# cslr_tsip register map
Vendor: Texas Instruments
Peripheral module from a debugger description file (folder c6472).
Registers are 32-bit, access not given, reset 0x0 unless marked. A register's access mark holds for its fields unless they carry their own. Offsets are as the file gives them; lines under a group give offsets from that group; [hi:lo] are bit positions; {n}, {i} and the like mark numbered series; 'fields as' and 'values as' point back to an identical list; <NAME> marks a mode.

## TSIP — TSIP MODULE REGISTERS
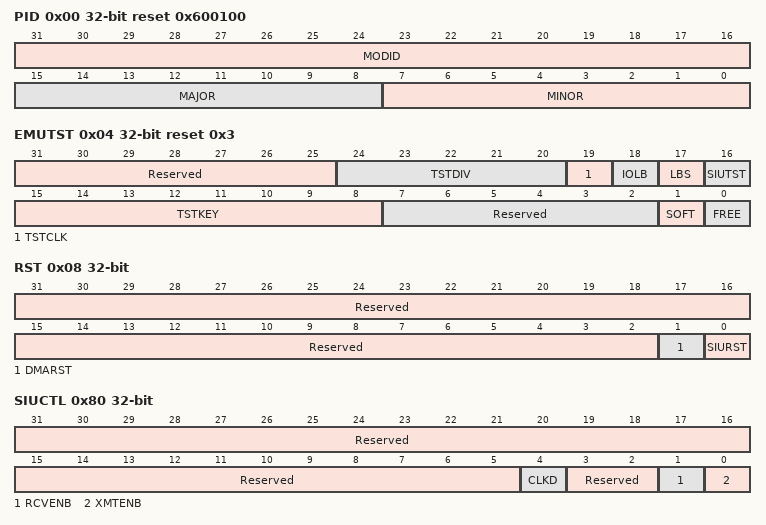
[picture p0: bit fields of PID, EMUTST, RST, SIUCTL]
0x00 PID ro reset 0x600100 — Peripheral Identification
  [31:16] MODID — Module Id
  [15:8] MAJOR — Major Version Value
  [7:0] MINOR — Minor Version Value
0x04 EMUTST reset 0x3 — Emulation and Test Register
  [31:25] Reserved — (access N)
  [24:20] TSTDIV rw — Internal Test Clock Divider Ratio
  [19] TSTCLK rw — Test Clock Source Selection
    0=EXTERNAL; 1=INTERNAL
  [18] IOLB rw — Serial Test mode selection
    0=INTERNAL_DLB; 1=IO_BUF_DLB
  [17] LBS rw — Serial Test mode selection
    0=DLB; 1=LLB
  [16] SIUTST rw — Number of MP and Shadow regions
    0=NORMAL_MODE; 1=LOOPBACK_MODE
  [15:8] TSTKEY rw — Test key
  [7:2] Reserved — (access N)
  [1] SOFT rw — Soft run selection
    0=DISABLE; 1=ENABLE
  [0] FREE rw — Free run selection
    0=DISABLE; 1=ENABLE
0x08 RST — Reset Register
  [31:2] Reserved — (access N)
  [1] DMARST rw — TDMU and DMATCU Reset
    1=RST
  [0] SIURST rw — SIU Reset
    1=RST
0x80 SIUCTL — SIU Global Control Register
  [31:5] Reserved — (access N)
  [4] CLKD rw — Clock Reduncy Selection
    0=REDUN; 1=DUAL
  [3:2] Reserved — (access N)
  [1] RCVENB rw — Receive Enable
    1=ENABLE; 0=DISABLE
  [0] XMTENB rw — Transmit Enable
    1=ENABLE; 0=DISABLE
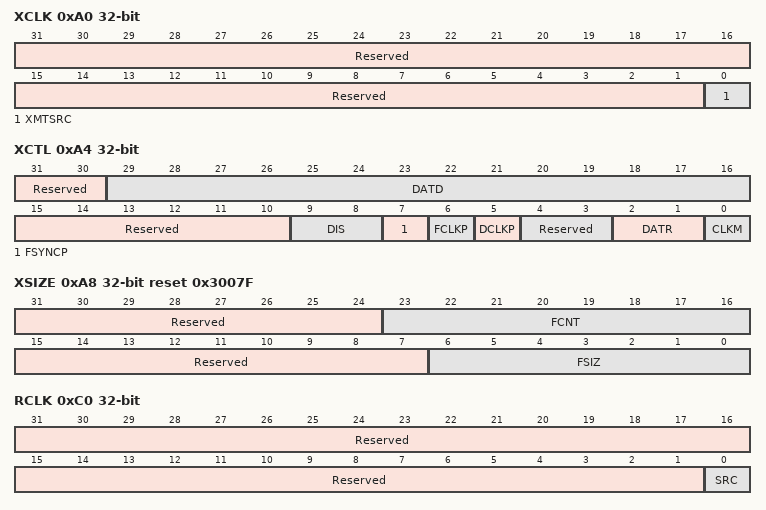
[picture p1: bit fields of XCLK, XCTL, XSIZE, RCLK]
0xA0 XCLK — Transmit Clock Source Register
  [31:1] Reserved — (access N)
  [0] XMTSRC rw — Transmit clock and frame sync selection
    0=ACLK; 1=BCLK
0xA4 XCTL — Transmit Control Register
  [31:30] Reserved — (access N)
  [29:16] DATD rw — Transmit data delay
  [15:10] Reserved — (access N)
  [9:8] DIS rw — Transmit output disable state
    0=HIMPED; 2=LOW; 3=HIGH
  [7] FSYNCP rw — Transmit frame sync polarity
    0=ALOW; 1=AHIGH
  [6] FCLKP rw — Transmit frame sync clock polarity
    0=RISING; 1=FALLING
  [5] DCLKP rw — Transmit data clock polarity
    0=RISING; 1=FALLING
  [4:3] Reserved — (access N)
  [2:1] DATR rw — Transmit data rate
    0=8M; 1=16M; 2=32M
  [0] CLKM rw — Transmit clock mode
    0=DBL; 1=SGL
0xA8 XSIZE reset 0x3007F — Transmit Size Register
  [31:24] Reserved — (access N)
  [23:16] FCNT rw — Transmit Frame count
  [15:7] Reserved — (access N)
  [6:0] FSIZ rw — Transmit Frame Size
0xC0 RCLK — Receive Clock Source Register
  [31:1] Reserved — (access N)
  [0] SRC rw — Receive clocl and frame sync selection
    0=ACLK; 1=BCLK
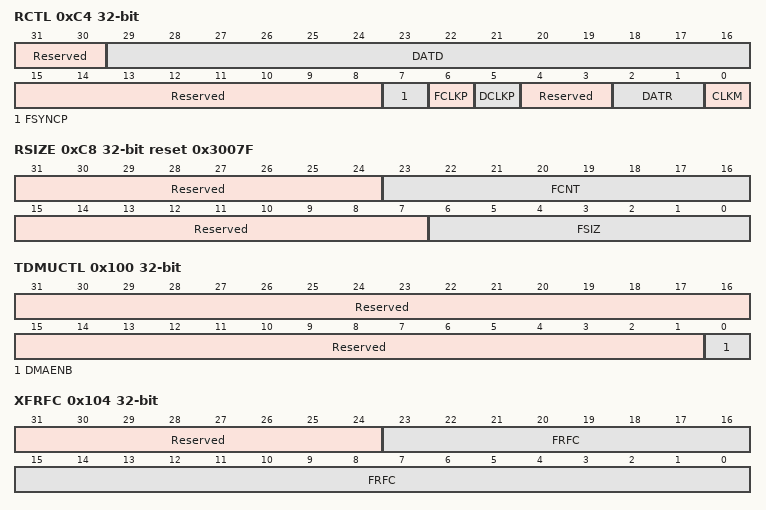
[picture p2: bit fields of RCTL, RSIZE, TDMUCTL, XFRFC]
0xC4 RCTL — Receive Control Register
  [31:30] Reserved — (access N)
  [29:16] DATD rw — Receive data delay
  [15:8] Reserved — (access N)
  [7] FSYNCP rw — Receive frame sync polarity
    0=ALOW; 1=AHIGH
  [6] FCLKP rw — Receive frame sync clock polarity
    0=RISING; 1=FALLING
  [5] DCLKP rw — Receive data clock polarity
    0=RISING; 1=FALLING
  [4:3] Reserved — (access N)
  [2:1] DATR rw — Receive Data rate
    0=8M; 1=16M; 2=32M
  [0] CLKM rw — Receive clock mode
    0=DBL; 1=SGL
0xC8 RSIZE reset 0x3007F — Receive size registers
  [31:24] Reserved — (access N)
  [23:16] FCNT rw — Receive frame count
  [15:7] Reserved — (access N)
  [6:0] FSIZ rw — Receive frme size
0x100 TDMUCTL — TDMU Global Control Register
  [31:1] Reserved — (access N)
  [0] DMAENB rw — TDMU and DMATCU enable
    1=ENB; 0=DIS
0x104 XFRFC — Transmit Free Running Frame Counter
  [31:24] Reserved — (access N)
  [23:0] FRFC ro — Free Running Frame Counter
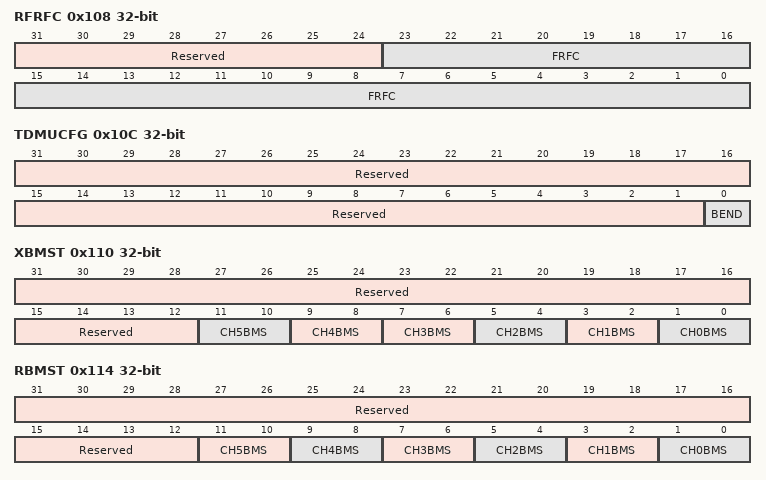
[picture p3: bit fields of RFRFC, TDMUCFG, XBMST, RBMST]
0x108 RFRFC — Receive Free Running Frame Counter
  fields as XFRFC
0x10C TDMUCFG — TDMU Global Configuration Register
  [31:1] Reserved — (access N)
  [0] BEND rw — Endian Mode Selection
    0=LITTLE; 1=BIG
0x110 XBMST — Transmit Channel Bitmap Active Status Register
  [31:12] Reserved — (access N)
  [11:10] CH5BMS ro — Transmit Channel 5 active status
  [9:8] CH4BMS ro — Transmit chaneel 4 active status
  [2n+1:2n] CH{n}BMS ro (n=0..3) — Transmit channel {n} active status
0x114 RBMST — Receive Channel Bitmap Active Status Register
  [31:12] Reserved — (access N)
  [2n+1:2n] CH{n}BMS ro (n=0..5) — Receive Channel {n} status
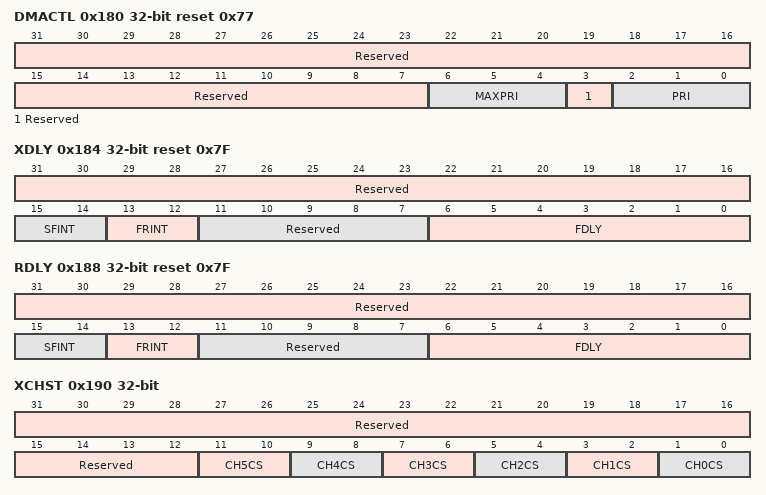
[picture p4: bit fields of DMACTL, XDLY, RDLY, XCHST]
0x180 DMACTL reset 0x77 — DMATCU Global Control Register
  [31:7] Reserved — (access N)
  [6:4] MAXPRI rw — Maximum Transfer Priority
  [3] Reserved — (access N)
  [2:0] PRI rw — Transfer Priority
0x184 XDLY reset 0x7F — Transmit timeslot delay counter
  [31:16] Reserved — (access N)
  [15:14] SFINT ro — Transmit Superframe interrupt selection
    0=ACK; 1=DLY; 2=ACKORDLY; 3=ACKNDLY
  [13:12] FRINT ro — Transmit Frame interrupt selection
    0=ACK; 1=DLY; 2=ACKORDLY; 3=ACKNDLY
  [11:7] Reserved — (access N)
  [6:0] FDLY rw — Transmit frame interrupt delay
0x188 RDLY reset 0x7F — Receive Timeslot Delay Counter
  [31:16] Reserved — (access N)
  [15:14] SFINT ro — Receive superframe interrupt selection
    0=ACK; 1=DLY; 2=ACKORDLY; 3=ACKNDLY
  [13:12] FRINT ro — Receive Frame interrupt selection
    0=ACK; 1=DLY; 2=ACKORDLY; 3=ACKNDLY
  [11:7] Reserved — (access N)
  [6:0] FDLY rw — Receive frame interrupt delay
0x190 XCHST — Transmit channel Configuration active status register
  [31:12] Reserved — (access N)
  [2n+1:2n] CH{n}CS ro (n=0..5) — Transmit channel {n} active status
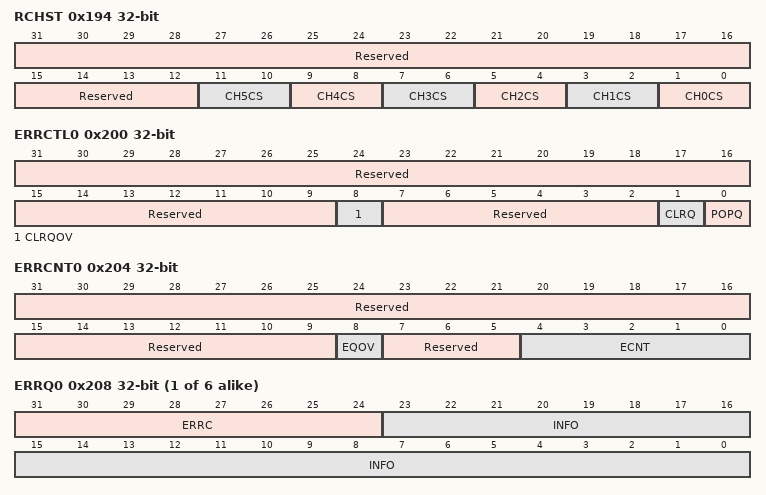
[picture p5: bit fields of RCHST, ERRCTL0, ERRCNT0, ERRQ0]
0x194 RCHST — Receive channel Configuration active status register
  [31:12] Reserved — (access N)
  [11:10] CH5CS ro — Receive channel 5 active status
  [9:8] CH4CS ro — Receive channel 4 active status
  [7:6] CH3CS ro — Receiev channel 3 active status
  [5:4] CH2CS ro — Receive channel 2 active status
  [3:2] CH1CS ro — Receive channel 1 active status
  [1:0] CH0CS ro — Receive channel 0 active status
0x200 ERRCTL0 — Transmit/Receive channel error control register {ERR_CTL}
  [31:9] Reserved — (access N)
  [8] CLRQOV rw — Clear error queue overflow flag
    1=CLR
  [7:2] Reserved — (access N)
  [1] CLRQ rw — Clear error queue
    1=CLR
  [0] POPQ rw — Pop the top entity off the error queue
    1=POP
0x200 ERRCTL0 — Transmit/Receive channel error control register {ERR_CTL}
  fields as ERRCTL0
0x204 ERRCNT0 — Transmit/Receive channel error count register {ERR_CNT}
  [31:9] Reserved — (access N)
  [8] EQOV ro — Error queue overflow
  [7:5] Reserved — (access N)
  [4:0] ECNT ro — Error count
{0x208+0x10*i} ERRQ{i} ro (i=0..5) — Transmit/Receive channel error queue register
  [31:24] ERRC — Error Code
  [23:0] INFO — Error information field
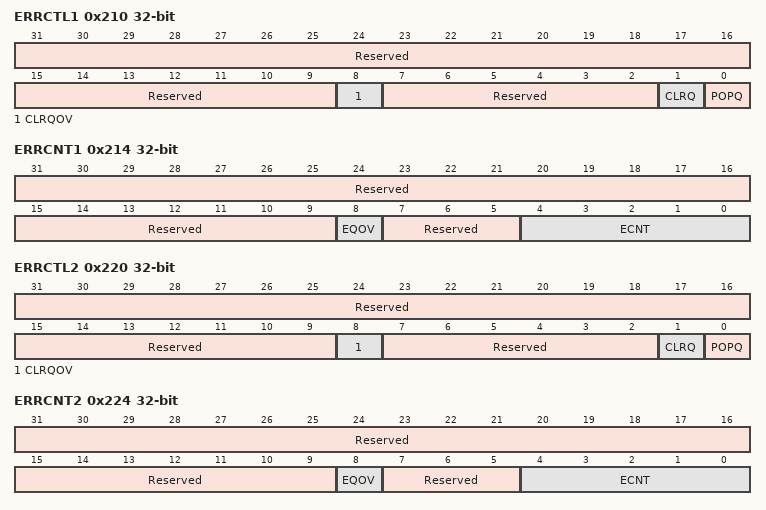
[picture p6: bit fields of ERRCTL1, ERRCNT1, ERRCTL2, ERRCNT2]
0x210 ERRCTL1 — Transmit/Receive channel error control register {ERR_CTL}
  fields as ERRCTL0
0x214 ERRCNT1 — Transmit/Receive channel error count register {ERR_CNT}
  fields as ERRCNT0
0x220 ERRCTL2 — Transmit/Receive channel error control register {ERR_CTL}
  fields as ERRCTL0
0x224 ERRCNT2 — Transmit/Receive channel error count register {ERR_CNT}
  fields as ERRCNT0
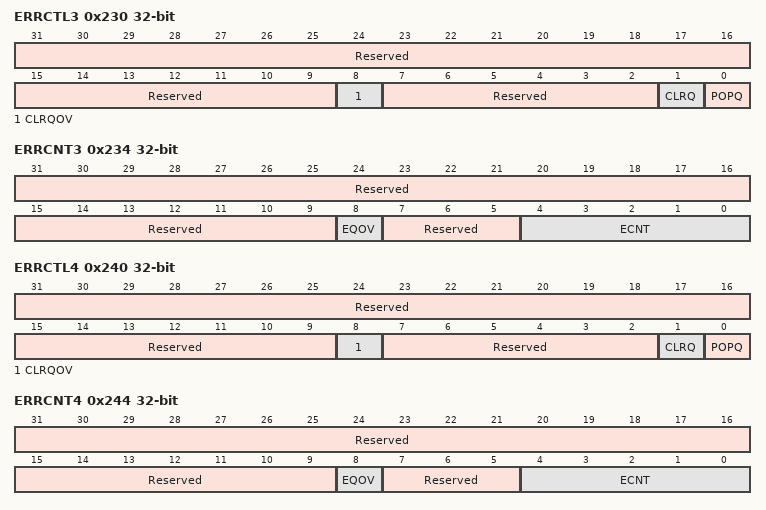
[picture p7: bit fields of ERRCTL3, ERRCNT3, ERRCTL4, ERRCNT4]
0x230 ERRCTL3 — Transmit/Receive channel error control register {ERR_CTL}
  fields as ERRCTL0
0x234 ERRCNT3 — Transmit/Receive channel error count register {ERR_CNT}
  fields as ERRCNT0
0x240 ERRCTL4 — Transmit/Receive channel error control register {ERR_CTL}
  fields as ERRCTL0
0x244 ERRCNT4 — Transmit/Receive channel error count register {ERR_CNT}
  fields as ERRCNT0
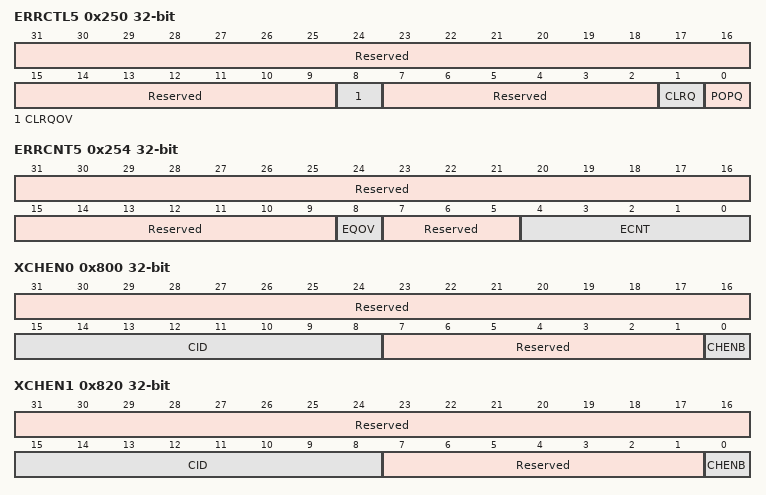
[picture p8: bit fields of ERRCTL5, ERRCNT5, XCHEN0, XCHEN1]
0x250 ERRCTL5 — Transmit/Receive channel error control register {ERR_CTL}
  fields as ERRCTL0
0x254 ERRCNT5 — Transmit/Receive channel error count register {ERR_CNT}
  fields as ERRCNT0
0x800 XCHEN0 — TDMU Transmit Channel Enable Register {XCHEN_XCHEN}
  [31:16] Reserved — (access N)
  [15:8] CID rw — configuration Identification
  [7:1] Reserved — (access N)
  [0] CHENB rw — Channel n enable
    1=ENB; 0=DIS
0x820 XCHEN1 — TDMU Transmit Channel Enable Register {XCHEN_XCHEN}
  fields as XCHEN0
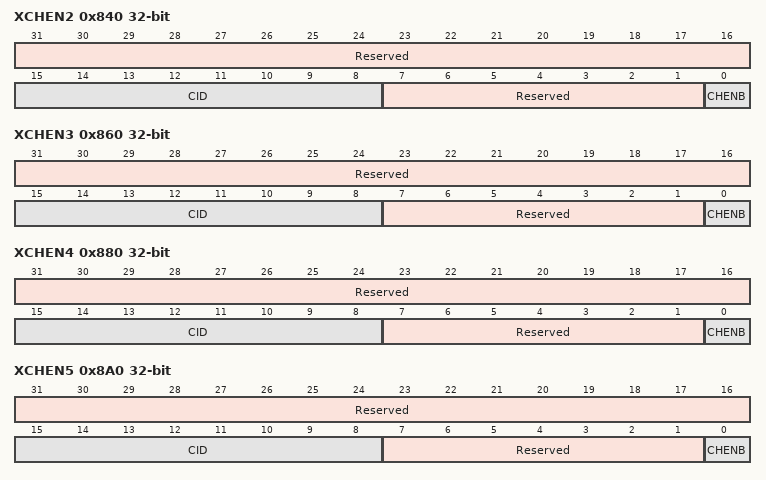
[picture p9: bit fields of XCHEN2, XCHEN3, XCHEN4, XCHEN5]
0x840 XCHEN2 — TDMU Transmit Channel Enable Register {XCHEN_XCHEN}
  fields as XCHEN0
0x860 XCHEN3 — TDMU Transmit Channel Enable Register {XCHEN_XCHEN}
  fields as XCHEN0
0x880 XCHEN4 — TDMU Transmit Channel Enable Register {XCHEN_XCHEN}
  fields as XCHEN0
0x8A0 XCHEN5 — TDMU Transmit Channel Enable Register {XCHEN_XCHEN}
  fields as XCHEN0
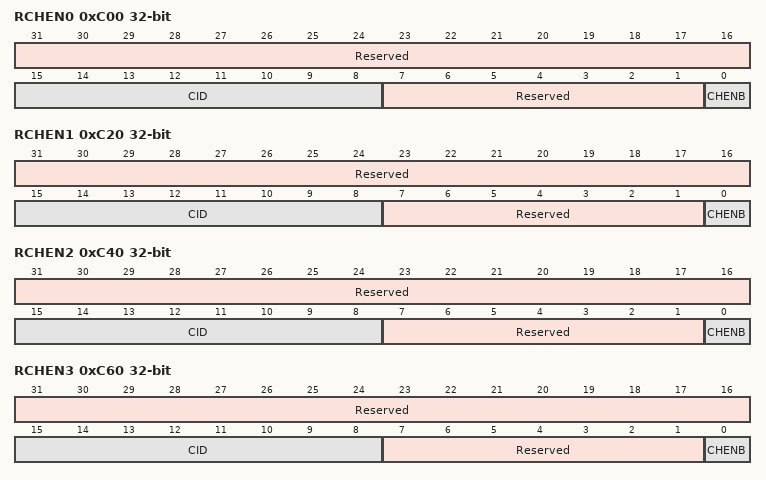
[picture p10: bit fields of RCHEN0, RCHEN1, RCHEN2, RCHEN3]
0xC00 RCHEN0 — TDMU Receive Channel Enable Register {RCHEN_RCHEN}
  fields as XCHEN0
0xC20 RCHEN1 — TDMU Receive Channel Enable Register {RCHEN_RCHEN}
  fields as XCHEN0
0xC40 RCHEN2 — TDMU Receive Channel Enable Register {RCHEN_RCHEN}
  fields as XCHEN0
0xC60 RCHEN3 — TDMU Receive Channel Enable Register {RCHEN_RCHEN}
  fields as XCHEN0
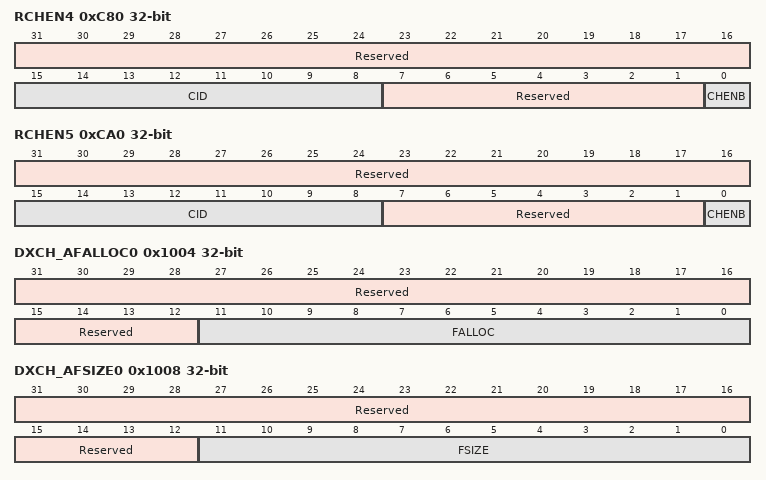
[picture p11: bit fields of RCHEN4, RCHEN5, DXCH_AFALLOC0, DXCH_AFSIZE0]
0xC80 RCHEN4 — TDMU Receive Channel Enable Register {RCHEN_RCHEN}
  fields as XCHEN0
0xCA0 RCHEN5 — TDMU Receive Channel Enable Register {RCHEN_RCHEN}
  fields as XCHEN0
0x1000 DXCH_ABASE0 rw — DMATCU Receive Channel Memory Base Address Register A {DXCH_ABASE}
  [31:0] BADDR — Memory Buffer Base Address
0x1004 DXCH_AFALLOC0 — DMATCU Receive Channel Frame Allocation Register A {DXCH_AFALLOC}
  [31:12] Reserved — (access N)
  [11:0] FALLOC rw — Frame Buffer Allocation
0x1008 DXCH_AFSIZE0 — DMATCU Receive Channel Frame Size Register A {DXCH_AFSIZE}
  [31:12] Reserved — (access N)
  [11:0] FSIZE rw — Frame Size
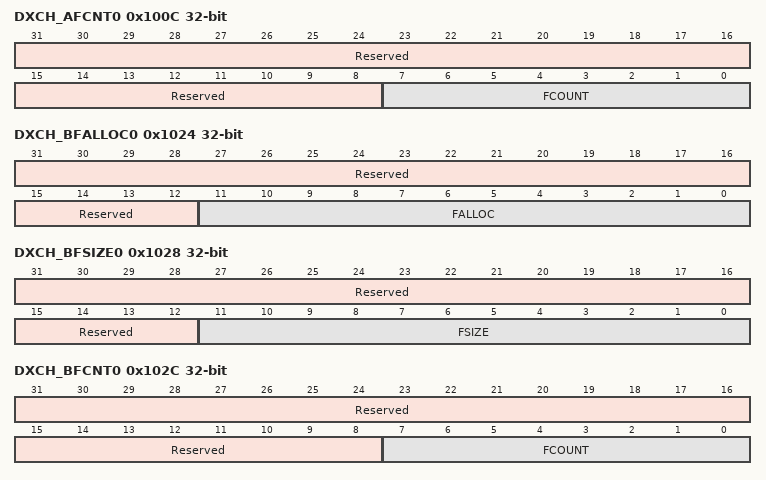
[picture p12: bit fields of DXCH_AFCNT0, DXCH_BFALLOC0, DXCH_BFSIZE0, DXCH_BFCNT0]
0x100C DXCH_AFCNT0 — DMATCU Receive Channel Frame Count Register A {DXCH_AFCNT}
  [31:8] Reserved — (access N)
  [7:0] FCOUNT rw — Frame count
0x1020 DXCH_BBASE0 rw — DMATCU Receive Channel Memory Base Address Register B {DXCH_BBASE}
  [31:0] BADDR — Memory Buffer Base Address
0x1024 DXCH_BFALLOC0 — DMATCU Receive Channel Frame Allocation Register B {DXCH_BFALLOC}
  fields as DXCH_AFALLOC0
0x1028 DXCH_BFSIZE0 — DMATCU Receive Channel Frame Size Register B {DXCH_BFSIZE}
  [31:12] Reserved — (access N)
  [11:0] FSIZE rw — Frame Size
0x102C DXCH_BFCNT0 — DMATCU Receive Channel Frame Count Register B {DXCH_BFCNT}
  [31:8] Reserved — (access N)
  [7:0] FCOUNT rw — Frame count
0x1040 DXCH_ABASE1 rw — DMATCU Receive Channel Memory Base Address Register A {DXCH_ABASE}
  [31:0] BADDR — Memory Buffer Base Address
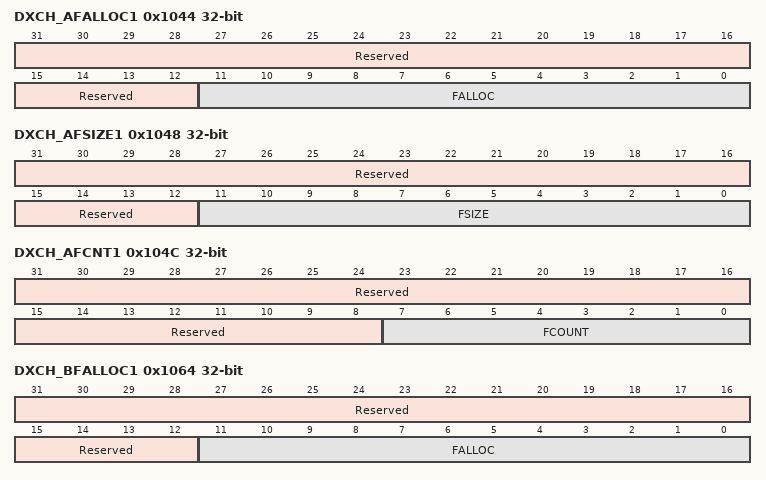
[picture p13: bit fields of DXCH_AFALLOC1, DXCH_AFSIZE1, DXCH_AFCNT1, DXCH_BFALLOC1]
0x1044 DXCH_AFALLOC1 — DMATCU Receive Channel Frame Allocation Register A {DXCH_AFALLOC}
  fields as DXCH_AFALLOC0
0x1048 DXCH_AFSIZE1 — DMATCU Receive Channel Frame Size Register A {DXCH_AFSIZE}
  [31:12] Reserved — (access N)
  [11:0] FSIZE rw — Frame Size
0x104C DXCH_AFCNT1 — DMATCU Receive Channel Frame Count Register A {DXCH_AFCNT}
  [31:8] Reserved — (access N)
  [7:0] FCOUNT rw — Frame count
0x1060 DXCH_BBASE1 rw — DMATCU Receive Channel Memory Base Address Register B {DXCH_BBASE}
  [31:0] BADDR — Memory Buffer Base Address
0x1064 DXCH_BFALLOC1 — DMATCU Receive Channel Frame Allocation Register B {DXCH_BFALLOC}
  fields as DXCH_AFALLOC0
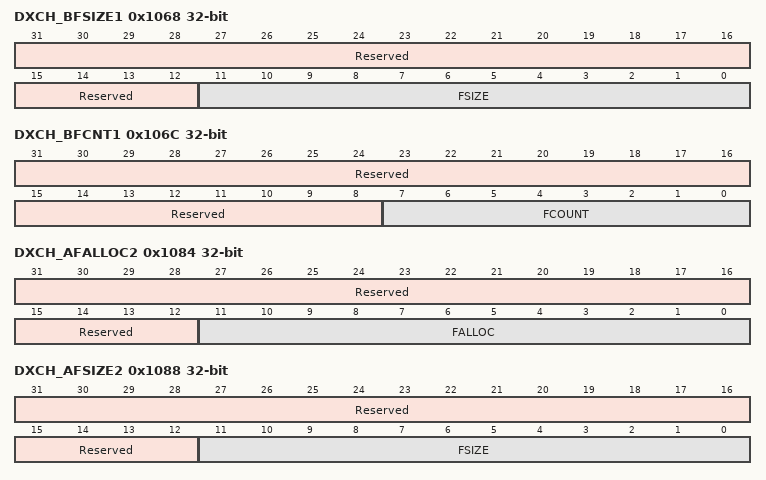
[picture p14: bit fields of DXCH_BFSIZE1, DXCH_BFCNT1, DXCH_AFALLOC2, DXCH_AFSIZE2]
0x1068 DXCH_BFSIZE1 — DMATCU Receive Channel Frame Size Register B {DXCH_BFSIZE}
  [31:12] Reserved — (access N)
  [11:0] FSIZE rw — Frame Size
0x106C DXCH_BFCNT1 — DMATCU Receive Channel Frame Count Register B {DXCH_BFCNT}
  [31:8] Reserved — (access N)
  [7:0] FCOUNT rw — Frame count
0x1080 DXCH_ABASE2 rw — DMATCU Receive Channel Memory Base Address Register A {DXCH_ABASE}
  [31:0] BADDR — Memory Buffer Base Address
0x1084 DXCH_AFALLOC2 — DMATCU Receive Channel Frame Allocation Register A {DXCH_AFALLOC}
  fields as DXCH_AFALLOC0
0x1088 DXCH_AFSIZE2 — DMATCU Receive Channel Frame Size Register A {DXCH_AFSIZE}
  [31:12] Reserved — (access N)
  [11:0] FSIZE rw — Frame Size
0x108C DXCH_AFCNT2 — DMATCU Receive Channel Frame Count Register A {DXCH_AFCNT}
  [31:8] Reserved — (access N)
  [7:0] FCOUNT rw — Frame count
0x10A0 DXCH_BBASE2 rw — DMATCU Receive Channel Memory Base Address Register B {DXCH_BBASE}
  [31:0] BADDR — Memory Buffer Base Address
0x10A4 DXCH_BFALLOC2 — DMATCU Receive Channel Frame Allocation Register B {DXCH_BFALLOC}
  fields as DXCH_AFALLOC0
0x10A8 DXCH_BFSIZE2 — DMATCU Receive Channel Frame Size Register B {DXCH_BFSIZE}
  [31:12] Reserved — (access N)
  [11:0] FSIZE rw — Frame Size
0x10AC DXCH_BFCNT2 — DMATCU Receive Channel Frame Count Register B {DXCH_BFCNT}
  [31:8] Reserved — (access N)
  [7:0] FCOUNT rw — Frame count
0x10C0 DXCH_ABASE3 rw — DMATCU Receive Channel Memory Base Address Register A {DXCH_ABASE}
  [31:0] BADDR — Memory Buffer Base Address
0x10C4 DXCH_AFALLOC3 — DMATCU Receive Channel Frame Allocation Register A {DXCH_AFALLOC}
  fields as DXCH_AFALLOC0
0x10C8 DXCH_AFSIZE3 — DMATCU Receive Channel Frame Size Register A {DXCH_AFSIZE}
  [31:12] Reserved — (access N)
  [11:0] FSIZE rw — Frame Size
0x10CC DXCH_AFCNT3 — DMATCU Receive Channel Frame Count Register A {DXCH_AFCNT}
  [31:8] Reserved — (access N)
  [7:0] FCOUNT rw — Frame count
0x10E0 DXCH_BBASE3 rw — DMATCU Receive Channel Memory Base Address Register B {DXCH_BBASE}
  [31:0] BADDR — Memory Buffer Base Address
0x10E4 DXCH_BFALLOC3 — DMATCU Receive Channel Frame Allocation Register B {DXCH_BFALLOC}
  fields as DXCH_AFALLOC0
0x10E8 DXCH_BFSIZE3 — DMATCU Receive Channel Frame Size Register B {DXCH_BFSIZE}
  [31:12] Reserved — (access N)
  [11:0] FSIZE rw — Frame Size
0x10EC DXCH_BFCNT3 — DMATCU Receive Channel Frame Count Register B {DXCH_BFCNT}
  [31:8] Reserved — (access N)
  [7:0] FCOUNT rw — Frame count
0x1100 DXCH_ABASE4 rw — DMATCU Receive Channel Memory Base Address Register A {DXCH_ABASE}
  [31:0] BADDR — Memory Buffer Base Address
0x1104 DXCH_AFALLOC4 — DMATCU Receive Channel Frame Allocation Register A {DXCH_AFALLOC}
  fields as DXCH_AFALLOC0
0x1108 DXCH_AFSIZE4 — DMATCU Receive Channel Frame Size Register A {DXCH_AFSIZE}
  [31:12] Reserved — (access N)
  [11:0] FSIZE rw — Frame Size
0x110C DXCH_AFCNT4 — DMATCU Receive Channel Frame Count Register A {DXCH_AFCNT}
  [31:8] Reserved — (access N)
  [7:0] FCOUNT rw — Frame count
0x1120 DXCH_BBASE4 rw — DMATCU Receive Channel Memory Base Address Register B {DXCH_BBASE}
  [31:0] BADDR — Memory Buffer Base Address
0x1124 DXCH_BFALLOC4 — DMATCU Receive Channel Frame Allocation Register B {DXCH_BFALLOC}
  fields as DXCH_AFALLOC0
0x1128 DXCH_BFSIZE4 — DMATCU Receive Channel Frame Size Register B {DXCH_BFSIZE}
  [31:12] Reserved — (access N)
  [11:0] FSIZE rw — Frame Size
0x112C DXCH_BFCNT4 — DMATCU Receive Channel Frame Count Register B {DXCH_BFCNT}
  [31:8] Reserved — (access N)
  [7:0] FCOUNT rw — Frame count
0x1140 DXCH_ABASE5 rw — DMATCU Receive Channel Memory Base Address Register A {DXCH_ABASE}
  [31:0] BADDR — Memory Buffer Base Address
0x1144 DXCH_AFALLOC5 — DMATCU Receive Channel Frame Allocation Register A {DXCH_AFALLOC}
  fields as DXCH_AFALLOC0
0x1148 DXCH_AFSIZE5 — DMATCU Receive Channel Frame Size Register A {DXCH_AFSIZE}
  [31:12] Reserved — (access N)
  [11:0] FSIZE rw — Frame Size
0x114C DXCH_AFCNT5 — DMATCU Receive Channel Frame Count Register A {DXCH_AFCNT}
  [31:8] Reserved — (access N)
  [7:0] FCOUNT rw — Frame count
0x1160 DXCH_BBASE5 rw — DMATCU Receive Channel Memory Base Address Register B {DXCH_BBASE}
  [31:0] BADDR — Memory Buffer Base Address
0x1164 DXCH_BFALLOC5 — DMATCU Receive Channel Frame Allocation Register B {DXCH_BFALLOC}
  fields as DXCH_AFALLOC0
0x1168 DXCH_BFSIZE5 — DMATCU Receive Channel Frame Size Register B {DXCH_BFSIZE}
  [31:12] Reserved — (access N)
  [11:0] FSIZE rw — Frame Size
0x116C DXCH_BFCNT5 — DMATCU Receive Channel Frame Count Register B {DXCH_BFCNT}
  [31:8] Reserved — (access N)
  [7:0] FCOUNT rw — Frame count
0x1800 DRCH_ABASE0 rw — DMATCU Receive Channel Memory Base Address Register A {DRCH_ABASE}
  [31:0] BADDR — Memory Buffer Base Address
0x1804 DRCH_AFALLOC0 — DMATCU Receive Channel Frame Allocation Register A {DRCH_AFALLOC}
  fields as DXCH_AFALLOC0
0x1808 DRCH_AFSIZE0 — DMATCU Receive Channel Frame Size Register A {DRCH_AFSIZE}
  [31:12] Reserved — (access N)
  [11:0] FSIZE rw — Frame Size
0x180C DRCH_AFCNT0 — DMATCU Receive Channel Frame Count Register A {DRCH_AFCNT}
  [31:8] Reserved — (access N)
  [7:0] FCOUNT rw — Frame count
0x1820 DRCH_BBASE0 rw — DMATCU Receive Channel Memory Base Address Register B {DRCH_BBASE}
  [31:0] BADDR — Memory Buffer Base Address
0x1824 DRCH_BFALLOC0 — DMATCU Receive Channel Frame Allocation Register B {DRCH_BFALLOC}
  fields as DXCH_AFALLOC0
0x1828 DRCH_BFSIZE0 — DMATCU Receive Channel Frame Size Register B {DRCH_BFSIZE}
  [31:12] Reserved — (access N)
  [11:0] FSIZE rw — Frame Size
0x182C DRCH_BFCNT0 — DMATCU Receive Channel Frame Count Register B {DRCH_BFCNT}
  [31:8] Reserved — (access N)
  [7:0] FCOUNT rw — Frame count
0x1840 DRCH_ABASE1 rw — DMATCU Receive Channel Memory Base Address Register A {DRCH_ABASE}
  [31:0] BADDR — Memory Buffer Base Address
0x1844 DRCH_AFALLOC1 — DMATCU Receive Channel Frame Allocation Register A {DRCH_AFALLOC}
  fields as DXCH_AFALLOC0
0x1848 DRCH_AFSIZE1 — DMATCU Receive Channel Frame Size Register A {DRCH_AFSIZE}
  [31:12] Reserved — (access N)
  [11:0] FSIZE rw — Frame Size
0x184C DRCH_AFCNT1 — DMATCU Receive Channel Frame Count Register A {DRCH_AFCNT}
  [31:8] Reserved — (access N)
  [7:0] FCOUNT rw — Frame count
0x1860 DRCH_BBASE1 rw — DMATCU Receive Channel Memory Base Address Register B {DRCH_BBASE}
  [31:0] BADDR — Memory Buffer Base Address
0x1864 DRCH_BFALLOC1 — DMATCU Receive Channel Frame Allocation Register B {DRCH_BFALLOC}
  fields as DXCH_AFALLOC0
0x1868 DRCH_BFSIZE1 — DMATCU Receive Channel Frame Size Register B {DRCH_BFSIZE}
  [31:12] Reserved — (access N)
  [11:0] FSIZE rw — Frame Size
0x186C DRCH_BFCNT1 — DMATCU Receive Channel Frame Count Register B {DRCH_BFCNT}
  [31:8] Reserved — (access N)
  [7:0] FCOUNT rw — Frame count
0x1880 DRCH_ABASE2 rw — DMATCU Receive Channel Memory Base Address Register A {DRCH_ABASE}
  [31:0] BADDR — Memory Buffer Base Address
0x1884 DRCH_AFALLOC2 — DMATCU Receive Channel Frame Allocation Register A {DRCH_AFALLOC}
  fields as DXCH_AFALLOC0
0x1888 DRCH_AFSIZE2 — DMATCU Receive Channel Frame Size Register A {DRCH_AFSIZE}
  [31:12] Reserved — (access N)
  [11:0] FSIZE rw — Frame Size
0x188C DRCH_AFCNT2 — DMATCU Receive Channel Frame Count Register A {DRCH_AFCNT}
  [31:8] Reserved — (access N)
  [7:0] FCOUNT rw — Frame count
0x18A0 DRCH_BBASE2 rw — DMATCU Receive Channel Memory Base Address Register B {DRCH_BBASE}
  [31:0] BADDR — Memory Buffer Base Address
0x18A4 DRCH_BFALLOC2 — DMATCU Receive Channel Frame Allocation Register B {DRCH_BFALLOC}
  fields as DXCH_AFALLOC0
0x18A8 DRCH_BFSIZE2 — DMATCU Receive Channel Frame Size Register B {DRCH_BFSIZE}
  [31:12] Reserved — (access N)
  [11:0] FSIZE rw — Frame Size
0x18AC DRCH_BFCNT2 — DMATCU Receive Channel Frame Count Register B {DRCH_BFCNT}
  [31:8] Reserved — (access N)
  [7:0] FCOUNT rw — Frame count
0x18C0 DRCH_ABASE3 rw — DMATCU Receive Channel Memory Base Address Register A {DRCH_ABASE}
  [31:0] BADDR — Memory Buffer Base Address
0x18C4 DRCH_AFALLOC3 — DMATCU Receive Channel Frame Allocation Register A {DRCH_AFALLOC}
  fields as DXCH_AFALLOC0
0x18C8 DRCH_AFSIZE3 — DMATCU Receive Channel Frame Size Register A {DRCH_AFSIZE}
  [31:12] Reserved — (access N)
  [11:0] FSIZE rw — Frame Size
0x18CC DRCH_AFCNT3 — DMATCU Receive Channel Frame Count Register A {DRCH_AFCNT}
  [31:8] Reserved — (access N)
  [7:0] FCOUNT rw — Frame count
0x18E0 DRCH_BBASE3 rw — DMATCU Receive Channel Memory Base Address Register B {DRCH_BBASE}
  [31:0] BADDR — Memory Buffer Base Address
0x18E4 DRCH_BFALLOC3 — DMATCU Receive Channel Frame Allocation Register B {DRCH_BFALLOC}
  fields as DXCH_AFALLOC0
0x18E8 DRCH_BFSIZE3 — DMATCU Receive Channel Frame Size Register B {DRCH_BFSIZE}
  [31:12] Reserved — (access N)
  [11:0] FSIZE rw — Frame Size
0x18EC DRCH_BFCNT3 — DMATCU Receive Channel Frame Count Register B {DRCH_BFCNT}
  [31:8] Reserved — (access N)
  [7:0] FCOUNT rw — Frame count
0x1900 DRCH_ABASE4 rw — DMATCU Receive Channel Memory Base Address Register A {DRCH_ABASE}
  [31:0] BADDR — Memory Buffer Base Address
0x1904 DRCH_AFALLOC4 — DMATCU Receive Channel Frame Allocation Register A {DRCH_AFALLOC}
  fields as DXCH_AFALLOC0
0x1908 DRCH_AFSIZE4 — DMATCU Receive Channel Frame Size Register A {DRCH_AFSIZE}
  [31:12] Reserved — (access N)
  [11:0] FSIZE rw — Frame Size
0x190C DRCH_AFCNT4 — DMATCU Receive Channel Frame Count Register A {DRCH_AFCNT}
  [31:8] Reserved — (access N)
  [7:0] FCOUNT rw — Frame count
0x1920 DRCH_BBASE4 rw — DMATCU Receive Channel Memory Base Address Register B {DRCH_BBASE}
  [31:0] BADDR — Memory Buffer Base Address
0x1924 DRCH_BFALLOC4 — DMATCU Receive Channel Frame Allocation Register B {DRCH_BFALLOC}
  fields as DXCH_AFALLOC0
0x1928 DRCH_BFSIZE4 — DMATCU Receive Channel Frame Size Register B {DRCH_BFSIZE}
  [31:12] Reserved — (access N)
  [11:0] FSIZE rw — Frame Size
0x192C DRCH_BFCNT4 — DMATCU Receive Channel Frame Count Register B {DRCH_BFCNT}
  [31:8] Reserved — (access N)
  [7:0] FCOUNT rw — Frame count
0x1940 DRCH_ABASE5 rw — DMATCU Receive Channel Memory Base Address Register A {DRCH_ABASE}
  [31:0] BADDR — Memory Buffer Base Address
0x1944 DRCH_AFALLOC5 — DMATCU Receive Channel Frame Allocation Register A {DRCH_AFALLOC}
  fields as DXCH_AFALLOC0
0x1948 DRCH_AFSIZE5 — DMATCU Receive Channel Frame Size Register A {DRCH_AFSIZE}
  [31:12] Reserved — (access N)
  [11:0] FSIZE rw — Frame Size
0x194C DRCH_AFCNT5 — DMATCU Receive Channel Frame Count Register A {DRCH_AFCNT}
  [31:8] Reserved — (access N)
  [7:0] FCOUNT rw — Frame count
0x1960 DRCH_BBASE5 rw — DMATCU Receive Channel Memory Base Address Register B {DRCH_BBASE}
  [31:0] BADDR — Memory Buffer Base Address
0x1964 DRCH_BFALLOC5 — DMATCU Receive Channel Frame Allocation Register B {DRCH_BFALLOC}
  fields as DXCH_AFALLOC0
0x1968 DRCH_BFSIZE5 — DMATCU Receive Channel Frame Size Register B {DRCH_BFSIZE}
  [31:12] Reserved — (access N)
  [11:0] FSIZE rw — Frame Size
0x196C DRCH_BFCNT5 — DMATCU Receive Channel Frame Count Register B {DRCH_BFCNT}
  [31:8] Reserved — (access N)
  [7:0] FCOUNT rw — Frame count
{0x8000+0x200*i} XBM_RBMA{i}[64] rw (i=0..5) — Transmit Channel Bitmap A
  [31:0] CH — Reserved
{0x8100+0x200*i} XBM_RBMB{i}[64] rw (i=0..5) — Transmit Channel Bitmap B
  [31:0] CH — Reserved
{0xC000+0x200*i} RBM_RBMA{i}[64] rw (i=0..5) — Receive Channel Bitmap A
  [31:0] CH — Reserved
{0xC100+0x200*i} RBM_RBMB{i}[64] rw (i=0..5) — Receive Channel Bitmap B
  [31:0] CH — Reserved
{0x10000+0x800*i} XPING{i} rw (i=0..2) — Transmit Channel {i} Ping buffer
  [31:0] DAT — Reserved
{0x10400+0x800*i} XPONG{i} rw (i=0..2) — Transmit Channel {i} Pong buffer
  [31:0] DAT — Reserved
0x11800 XPING3 rw — Transmit Channel 0 Ping buffer
  [31:0] DAT — Reserved
0x11C00 XPONG3 rw — Transmit Channel 0 Pong buffer
  [31:0] DAT — Reserved
0x12000 XPING4 rw — Transmit Channel 4 Ping buffer
  [31:0] DAT — Reserved
0x12400 XPONG4 rw — Transmit Channel 4 Ping buffer
  [31:0] DAT — Reserved
0x12800 XPING5 rw — Transmit Channel 5 Ping buffer
  [31:0] DAT — Reserved
0x12C00 XPONG5 rw — Transmit Channel 5 Pong buffer
  [31:0] DAT — Reserved
{0x18000+0x800*i} RPING{i} rw (i=0..2) — Receive Channel {i} Ping buffer
  [31:0] DAT — Reserved
{0x18400+0x800*i} RPONG{i} rw (i=0..2) — Receive Channel {i} Pong buffer
  [31:0] DAT — Reserved
0x19800 RPING3 rw — Receive Channel 0 Ping buffer
  [31:0] DAT — Reserved
0x19C00 RPONG3 rw — Receive Channel 0 Pong buffer
  [31:0] DAT — Reserved
0x1A000 RPING4 rw — Receive Channel 4 Ping buffer
  [31:0] DAT — Reserved
0x1A400 RPONG4 rw — Receive Channel 4 Ping buffer
  [31:0] DAT — Reserved
0x1A800 RPING5 rw — Receive Channel 5 Ping buffer
  [31:0] DAT — Reserved
0x1AC00 RPONG5 rw — Receive Channel 5 Pong buffer
  [31:0] DAT — Reserved
